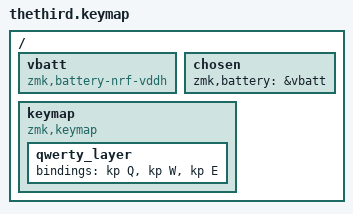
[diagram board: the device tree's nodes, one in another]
#include <behaviors.dtsi>
#include <dt-bindings/zmk/keys.h>
#include <dt-bindings/zmk/bt.h>
#include <dt-bindings/zmk/outputs.h>
#include <dt-bindings/zmk/ext_power.h>

#define QWERTY 0

/ {
    vbatt: vbatt {
                compatible = "zmk,battery-nrf-vddh";
        };
        chosen {
                zmk,battery = &vbatt;
        };

keymap {
        compatible = "zmk,keymap";

        qwerty_layer { //0
            bindings = <
                &kp Q   &kp W   &kp E
                >;
        };
    };
};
